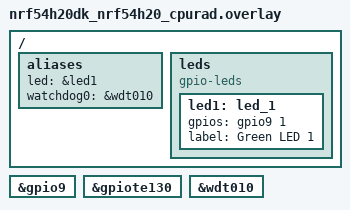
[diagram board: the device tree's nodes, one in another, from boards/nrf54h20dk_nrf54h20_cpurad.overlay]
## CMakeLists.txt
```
#
# Copyright (c) 2024 Nordic Semiconductor ASA
#
# SPDX-License-Identifier: LicenseRef-Nordic-5-Clause
#

cmake_minimum_required(VERSION 3.20.0)

find_package(Zephyr REQUIRED HINTS $ENV{ZEPHYR_BASE})

if(NOT SYSBUILD)
  message(FATAL_ERROR
    " This is a multi-image application that should be built using sysbuild.\n"
    " Add --sysbuild argument to west build command to prepare all the images."
  )
endif()

project(idle_wdt)

target_sources(app PRIVATE src/main.c)
```

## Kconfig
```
#
# Copyright (c) 2024 Nordic Semiconductor ASA
#
# SPDX-License-Identifier: LicenseRef-Nordic-5-Clause
#

config TEST_SLEEP_DURATION_MS
	int "Core sleep duration (miliseconds)"
	default 1000
	help
	  Set sleep duration to TEST_SLEEP_DURATION_MS miliseconds.
	  Based on the value of 'min-residency-us' specified for each power state defined in the DTS,
	  core enters the lowest possible power state.

config TEST_SYNCHRONIZE_CORES
	bool "Synchronization with other core"
	help
	  When set to 'y' core will synchronize code execution with the other core.

source "Kconfig.zephyr"
```

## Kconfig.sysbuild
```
#
# Copyright (c) 2024 Nordic Semiconductor ASA
#
# SPDX-License-Identifier: LicenseRef-Nordic-5-Clause
#

choice NETCORE
	default NETCORE_REMOTE

config NETCORE_REMOTE
	bool "Remote image"

config NETCORE_REMOTE_SLEEP_FOREVER
	bool "Remote sleep forever image"

endchoice

config NETCORE_IMAGE_NAME
	default "remote" if NETCORE_REMOTE
	default "remote_sleep_forever" if NETCORE_REMOTE_SLEEP_FOREVER

config NETCORE_IMAGE_PATH
	default "$(ZEPHYR_NRF_MODULE_DIR)/tests/benchmarks/multicore/idle_wdt/remote" if NETCORE_REMOTE
	default "$(ZEPHYR_NRF_MODULE_DIR)/tests/benchmarks/power_consumption/common/remote_sleep_forever" if NETCORE_REMOTE_SLEEP_FOREVER

choice APPCORE
	default APPCORE_REMOTE_SLEEP_FOREVER

config APPCORE_REMOTE_SLEEP_FOREVER
	bool "Remote sleep forever image"

endchoice

config APPCORE_IMAGE_NAME
	default "remote_sleep_forever" if APPCORE_REMOTE_SLEEP_FOREVER

config APPCORE_IMAGE_PATH
	default "$(ZEPHYR_NRF_MODULE_DIR)/tests/benchmarks/power_consumption/common/remote_sleep_forever" if APPCORE_REMOTE_SLEEP_FOREVER

choice PPRCORE
	default PPRCORE_REMOTE_SLEEP_FOREVER if SOC_NRF9251_CPUAPP
	default PPRCORE_NONE

config PPRCORE_REMOTE_SLEEP_FOREVER
	bool "Remote sleep forever image"

endchoice

config PPRCORE_IMAGE_NAME
	default "remote_sleep_forever" if PPRCORE_REMOTE_SLEEP_FOREVER

config PPRCORE_IMAGE_PATH
	default "$(ZEPHYR_NRF_MODULE_DIR)/tests/benchmarks/power_consumption/common/remote_sleep_forever" if PPRCORE_REMOTE_SLEEP_FOREVER

config TEST_SYNCHRONIZE_CORES
	bool "Synchronize both cores"
	depends on NETCORE_REMOTE
	default y
	help
	  When set to 'y' both cores will synchronize just before entering the main loop.
	  This requires test code to be compiled for both Application and Radio cores.
	  When one of the cores is flashed with remote_sleep_forever it will not confirm its readines.
	  In such case, the other core will wait forever for event that never happens.

source "share/sysbuild/Kconfig"
```

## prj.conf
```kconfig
CONFIG_PRINTK=y
CONFIG_LOG=y
CONFIG_LOG_MODE_IMMEDIATE=y
CONFIG_ASSERT=y
CONFIG_WATCHDOG=y
```

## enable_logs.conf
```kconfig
#
# Copyright (c) 2025 Nordic Semiconductor ASA
#
# SPDX-License-Identifier: LicenseRef-Nordic-5-Clause
#

CONFIG_PM=n
CONFIG_PM_DEVICE=n
CONFIG_PM_DEVICE_RUNTIME=n

CONFIG_PRINTK=y
CONFIG_LOG=y
CONFIG_CONSOLE=y
CONFIG_UART_CONSOLE=y
CONFIG_SERIAL=y
```

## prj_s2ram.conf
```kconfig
CONFIG_PM=y
CONFIG_POWEROFF=y

CONFIG_PM_DEVICE=y
CONFIG_PM_DEVICE_RUNTIME=y

# Enable for debugging purposes only
CONFIG_BOOT_BANNER=n
CONFIG_NCS_BOOT_BANNER=n
CONFIG_PRINTK=n
CONFIG_LOG=n
CONFIG_CONSOLE=n
CONFIG_UART_CONSOLE=n
CONFIG_SERIAL=n

CONFIG_WATCHDOG=y
CONFIG_ASSERT=y
```

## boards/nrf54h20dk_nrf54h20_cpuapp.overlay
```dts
/*
 * Copyright (c) 2024 Nordic Semiconductor ASA
 *
 * SPDX-License-Identifier: LicenseRef-Nordic-5-Clause
 */

/ {
	aliases {
		led = &led0;
		watchdog0 = &wdt010;
		/delete-property/ led1;
	};
};

/delete-node/ &led1;

&wdt010 {
	status = "okay";
};

&gpio6 {
	status = "disabled";
};

&exmif {
	status = "disabled";
};
```

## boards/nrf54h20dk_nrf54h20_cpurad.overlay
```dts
/*
 * Copyright (c) 2025 Nordic Semiconductor ASA
 *
 * SPDX-License-Identifier: LicenseRef-Nordic-5-Clause
 */

/ {
	aliases {
		led = &led1;
		watchdog0 = &wdt010;
	};

	leds {
		compatible = "gpio-leds";

		led1: led_1 {
			gpios = <&gpio9 1 GPIO_ACTIVE_HIGH>;
			label = "Green LED 1";
		};
	};
};

&gpio9 {
	status = "okay";
};

&gpiote130 {
	status = "okay";
};

&wdt010 {
	status = "okay";
};
```

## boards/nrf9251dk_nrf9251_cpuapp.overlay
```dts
/*
 * Copyright (c) 2026 Nordic Semiconductor ASA
 *
 * SPDX-License-Identifier: LicenseRef-Nordic-5-Clause
 */

/ {
	aliases {
		led = &led0;
		watchdog0 = &wdt010;
	};
};

&wdt010 {
	status = "okay";
};

&led1 {
	/* Move to other GPIO. */
	gpios = <&gpio2 1 (GPIO_PULL_DOWN | GPIO_ACTIVE_HIGH)>;
};

&cpuppr_vpr {
	status = "okay";
};

&uart132 {
	status = "reserved";
	interrupt-parent = <&cpuppr_clic>;
};
```

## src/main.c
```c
/*
 * Copyright (c) 2024 Nordic Semiconductor ASA
 *
 * SPDX-License-Identifier: LicenseRef-Nordic-5-Clause
 */

#include <zephyr/logging/log.h>
LOG_MODULE_REGISTER(idle_wdt, LOG_LEVEL_INF);

#include <zephyr/kernel.h>
#include <zephyr/cache.h>
#include <zephyr/drivers/watchdog.h>
#include <zephyr/drivers/gpio.h>

static const struct gpio_dt_spec led = GPIO_DT_SPEC_GET(DT_ALIAS(led), gpios);

#define WDT_WINDOW_MAX	(200)

/* Watchdog related variables */
static const struct device *const my_wdt_device = DEVICE_DT_GET(DT_ALIAS(watchdog0));
static struct wdt_timeout_cfg m_cfg_wdt0;
static int my_wdt_channel;

/* No init section will contain WDT_TAG if watchdog has fired */
#define WDT_TAG					(12345678U)

#if DT_NODE_HAS_STATUS(DT_CHOSEN(zephyr_dtcm), okay)
#define NOINIT_SECTION ".dtcm_noinit.test_wdt"
#else
#define NOINIT_SECTION ".noinit.test_wdt"
#endif
static volatile uint32_t wdt_status __attribute__((section(NOINIT_SECTION)));

#if defined(CONFIG_TEST_SYNCHRONIZE_CORES)
#define SHM_START_ADDR		(DT_REG_ADDR(DT_NODELABEL(cpuapp_cpurad_ipc_shm)))
volatile static uint32_t *shared_var = (volatile uint32_t *) SHM_START_ADDR;
#define HOST_IS_READY	(1)
#define REMOTE_IS_READY	(2)
#endif

/* Variables used to make CPU active for ~1 second */
static struct k_timer my_timer;
static bool timer_expired;

static void wdt_int_cb(const struct device *wdt_dev, int channel_id)
{
	ARG_UNUSED(wdt_dev);
	ARG_UNUSED(channel_id);
	wdt_status = WDT_TAG;
}

void my_timer_handler(struct k_timer *dummy)
{
	timer_expired = true;
}

int main(void)
{
	int ret;
	int counter = 0;

	ret = gpio_is_ready_dt(&led);
	__ASSERT(ret, "Error: GPIO Device not ready");

	ret = gpio_pin_configure_dt(&led, GPIO_OUTPUT_ACTIVE);
	__ASSERT(ret == 0, "Could not configure led GPIO");

	LOG_INF("Multicore idle_wdt test on %s", CONFIG_BOARD_TARGET);
	LOG_INF("Main sleeps for %d ms", CONFIG_TEST_SLEEP_DURATION_MS);
#if defined(CONFIG_TEST_SYNCHRONIZE_CORES)
	LOG_INF("Shared memory at %p", (void *) shared_var);
#endif

	k_timer_init(&my_timer, my_timer_handler, NULL);

	ret = device_is_ready(my_wdt_device);
	if (!ret) {
		LOG_ERR("WDT device %s is not ready", my_wdt_device->name);
	}
	__ASSERT(ret, "WDT device %s is not ready\n", my_wdt_device->name);

	/* When watchdog fires, variable wdt_status is set to the value of WDT_TAG
	 * in WDT callback wdt_int_cb(). Then, target is reset.
	 * Check value of wdt_status to prevent reset loop.
	 */
	if (wdt_status == WDT_TAG) {
		LOG_INF("Watchod has fired");
		/* Pinreset shall "recover" test to initial state */
		wdt_status = 0U;
		__ASSERT(false, "Watchod has fired\n");
	} else {
		LOG_INF("Reset wasn't due to watchdog.");
	}

	LOG_INF("wdt_status = %u", wdt_status);
	/* Clear flag that is set when the watchdog fires */
	wdt_status = 0U;
	LOG_INF("wdt_status = %u", wdt_status);

	/* Configure Watchdog */
	m_cfg_wdt0.callback = wdt_int_cb;
	m_cfg_wdt0.flags = WDT_FLAG_RESET_SOC;
	m_cfg_wdt0.window.min = 0U;
	m_cfg_wdt0.window.max = WDT_WINDOW_MAX;
	my_wdt_channel = wdt_install_timeout(my_wdt_device, &m_cfg_wdt0);
	if (my_wdt_channel < 0) {
		LOG_ERR("wdt_install_timeout() returned %d", my_wdt_channel);
		__ASSERT(false, "wdt_install_timeout() returned %d\n", my_wdt_channel);
	}

#if defined(CONFIG_TEST_SYNCHRONIZE_CORES)
/* Synchronize Remote core with Host core */
#if !defined(CONFIG_TEST_ROLE_REMOTE)
	LOG_DBG("HOST starts");
	*shared_var = HOST_IS_READY;
	sys_cache_data_flush_range((void *) shared_var, sizeof(*shared_var));
	LOG_DBG("HOST wrote HOST_IS_READY: %u", *shared_var);
	while (*shared_var != REMOTE_IS_READY) {
		k_msleep(1);
		sys_cache_data_invd_range((void *) shared_var, sizeof(*shared_var));
		LOG_DBG("shared_var is: %u", *shared_var);
	}
	LOG_INF("HOST continues");
#else /* !defined(CONFIG_TEST_ROLE_REMOTE) */
	LOG_DBG("REMOTE starts");
	while (*shared_var != HOST_IS_READY) {
		k_msleep(1);
		sys_cache_data_invd_range((void *) shared_var, sizeof(*shared_var));
		LOG_DBG("shared_var is: %u", *shared_var);
	}
	LOG_DBG("REMOTE found that HOST_IS_READY");
	*shared_var = REMOTE_IS_READY;
	sys_cache_data_flush_range((void *) shared_var, sizeof(*shared_var));
	LOG_DBG("REMOTE wrote REMOTE_IS_READY: %u", *shared_var);
	LOG_INF("REMOTE continues");
#endif /* !defined(CONFIG_TEST_ROLE_REMOTE) */
#endif /* defined(CONFIG_TEST_SYNCHRONIZE_CORES) */

	/* Start Watchdog */
	ret = wdt_setup(my_wdt_device, WDT_OPT_PAUSE_HALTED_BY_DBG | WDT_OPT_PAUSE_IN_SLEEP);
	if (ret < 0) {
		LOG_ERR("wdt_setup() returned %d", ret);
		__ASSERT(false, "wdt_setup() returned %d\n", ret);
	}

	/* Run test forever */
	while (1) {
		timer_expired = false;

		/* start a one-shot timer that expires after 1 second */
		k_timer_start(&my_timer, K_MSEC(1000), K_NO_WAIT);

		/* Keep CPU active for ~ 1 second */
		while (!timer_expired) {
			ret = wdt_feed(my_wdt_device, my_wdt_channel);
			if (ret < 0) {
				LOG_ERR("wdt_feed() returned: %d", ret);
				/* Stop watchdog */
				wdt_disable(my_wdt_device);
				__ASSERT(false, "wdt_feed() returned: %d\n", ret);
			}
			k_busy_wait(10000);
			k_yield();
		}

		LOG_INF("Run %d", counter);
		counter++;

		/* Sleep / enter low power state
		 * Watchdog was started with option WDT_OPT_PAUSE_IN_SLEEP thus
		 * it shall not reset the core during sleep.
		 */
		gpio_pin_set_dt(&led, 0);
		k_msleep(CONFIG_TEST_SLEEP_DURATION_MS);
		gpio_pin_set_dt(&led, 1);
	}

	return 0;
}
```
